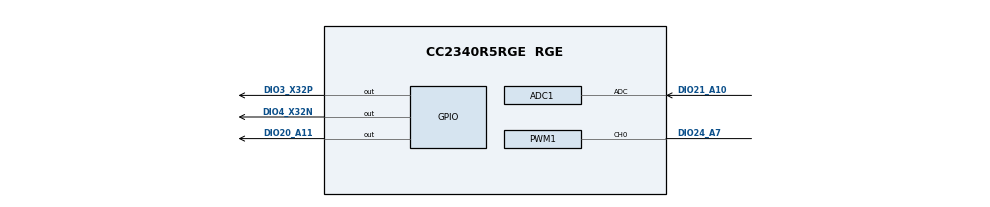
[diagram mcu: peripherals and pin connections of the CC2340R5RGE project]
/**
 * @cliArgs --device "CC2340R5RGE" --part "Default" --package "RGE" --rtos "freertos" --product "simplelink_lowpower_f3_sdk@8.40.02.01"
 * @versions {"tool":"1.22.0+3893"}
 */

/**
 * Import the modules used in this configuration.
 */
const FreeRTOS       = scripting.addModule("/freertos/FreeRTOS");
const CCFG           = scripting.addModule("/ti/devices/CCFG");
const rfdesign       = scripting.addModule("/ti/devices/radioconfig/rfdesign");
const ADC            = scripting.addModule("/ti/drivers/ADC", {}, false);
const ADC1           = ADC.addInstance();
const BatteryMonitor = scripting.addModule("/ti/drivers/BatteryMonitor");
const GPIO           = scripting.addModule("/ti/drivers/GPIO");
const GPIO2          = GPIO.addInstance();
const GPIO3          = GPIO.addInstance();
const GPIO4          = GPIO.addInstance();
const PWM            = scripting.addModule("/ti/drivers/PWM", {}, false);
const PWM1           = PWM.addInstance();
const Settings       = scripting.addModule("/ti/posix/freertos/Settings");
const zigbee         = scripting.addModule("/ti/zigbee/zigbee");

/**
 * Write custom configuration values to the imported modules.
 */
FreeRTOS.heapSize       = 0x00001BBC;
FreeRTOS.idleStackSize  = 0x00000100;
FreeRTOS.timerStackSize = 0x00000100;

CCFG.srcClkLF           = "LF RCOSC";
CCFG.ccfgTemplate.$name = "ti_devices_CCFG_CCFGCC23X0Template0";

rfdesign.rfDesign = "LP_EM_CC2340R5_RGE_4X4_IS24";

ADC1.$name                         = "CONFIG_ADC_0";
ADC1.adcChannel.adc.$assign        = "ADC";
ADC1.adcChannel.adc.adcPin.$assign = "DIO21_A10";

GPIO2.mode            = "Output";
GPIO2.$name           = "CONFIG_GPIO_GLED";
GPIO2.gpioPin.$assign = "DIO3_X32P";

GPIO3.mode            = "Output";
GPIO3.$name           = "CONFIG_GPIO_RLED";
GPIO3.gpioPin.$assign = "DIO4_X32N";

GPIO4.$name            = "CONFIG_GPIO_BTN1";
GPIO4.pull             = "Pull Up";
GPIO4.interruptTrigger = "Falling Edge";
GPIO4.gpioPin.$assign  = "DIO20_A11";

PWM1.$name                            = "CONFIG_PWM_0";
PWM1.timerObject.$name                = "CONFIG_LGPTIMER_0";
PWM1.timerObject.channel0Connection   = "Pin";
PWM1.timerObject.timer.$assign        = "LGPT1";
PWM1.timerObject.timer.ch0Pin.$assign = "DIO24_A7";
PWM1.timerObject.ch0PinInstance.pull  = "Pull Up";

zigbee.primaryChannels                   = [11,12,13,14,15,16,17,18,19,20,21,22,23,24,25,26];
zigbee.deviceType                        = ["zed"];
zigbee.loggingEnabled                    = true;
zigbee.nvs.internalFlash.regionBase      = 0x7F000;
zigbee.LogModuleZigbeeLLMAC.enableModule = false;
zigbee.LogModuleZigbeeApp.enable_INFO    = true;
zigbee.LogModuleZigbeeApp.enable_VERBOSE = true;
zigbee.LogModuleZigbeeApp.enable_DEBUG   = true;

const RNG       = scripting.addModule("/ti/drivers/RNG", {}, false);
RNG.rngPoolSize = 512;
scripting.suppress("This the default noise conditioning key provided by TI, which is acceptable per NIST SP 800-90B\\. However, TI recommends you change this default value to a custom random value for your product", RNG, "noiseConditioningKeyW3");

const LogSinkBuf                   = scripting.addModule("/ti/log/LogSinkBuf", {}, false);
const LogSinkBuf1                  = LogSinkBuf.addInstance({}, false);
LogSinkBuf1.$name                  = "CONFIG_ti_log_LogSinkBuf_0";
zigbee.LogModuleZigbeeLLMAC.logger = LogSinkBuf1;
zigbee.LogModuleZigbeeApp.logger   = LogSinkBuf1;
